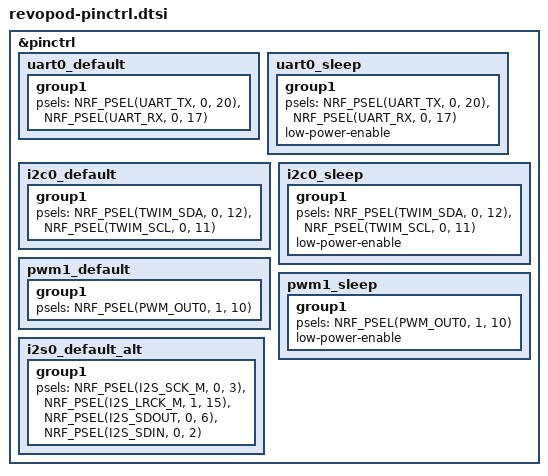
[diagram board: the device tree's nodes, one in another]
/*
 * Copyright (c) 2022 Nordic Semiconductor
 * SPDX-License-Identifier: Apache-2.0
 */

&pinctrl {
	uart0_default: uart0_default {
		group1 {
			psels = <NRF_PSEL(UART_TX, 0, 20)>,
				<NRF_PSEL(UART_RX, 0, 17)>;
		};
	};

	uart0_sleep: uart0_sleep {
		group1 {
			psels = <NRF_PSEL(UART_TX, 0, 20)>,
				<NRF_PSEL(UART_RX, 0, 17)>;
			low-power-enable;
		};
	};

	i2c0_default: i2c0_default {
		group1 {
			psels = <NRF_PSEL(TWIM_SDA, 0, 12)>,
				<NRF_PSEL(TWIM_SCL, 0, 11)>;
		};
	};

	i2c0_sleep: i2c0_sleep {
		group1 {
			psels = <NRF_PSEL(TWIM_SDA, 0, 12)>,
				<NRF_PSEL(TWIM_SCL, 0, 11)>;
			low-power-enable;
		};
	};

	pwm1_default: pwm1_default {
		group1 {
			psels = <NRF_PSEL(PWM_OUT0, 1, 10)>;

		};
	};

	pwm1_sleep: pwm1_sleep {
		group1 {
			psels = <NRF_PSEL(PWM_OUT0, 1, 10)>;
			low-power-enable;
		};
	};
	// spi1_default: spi1_default {
    //     group1 {
    //         psels = <NRF_PSEL(SPIM_SCK, 0, 31)>,
    //             <NRF_PSEL(SPIM_MOSI, 0, 6)>,
    //             <NRF_PSEL(SPIM_MISO, 0, 2)>;
    //     };
    // };
	// spi1_sleep: spi1_sleep {
    //     group1 {
    //         psels = <NRF_PSEL(SPIM_SCK, 0, 31)>,
    //             <NRF_PSEL(SPIM_MOSI, 0, 6)>,
    //             <NRF_PSEL(SPIM_MISO, 0, 2)>;
    //         low-power-enable;
    //     };
	// };
	// spi1_default: spi1_default {
    //     group1 {
    //         psels = <NRF_PSEL(SPIM_MOSI, 0, 6)>;
    //     };
    // };

    // spi1_sleep: spi1_sleep {
    //     group1 {
    //         psels = <NRF_PSEL(SPIM_MOSI, 0, 6)>;
    //         low-power-enable;
    //     };
    // };

	i2s0_default_alt: i2s0_default_alt {
		group1 {
			psels = <NRF_PSEL(I2S_SCK_M, 0, 3)>,
				<NRF_PSEL(I2S_LRCK_M, 1, 15)>,
				<NRF_PSEL(I2S_SDOUT, 0, 6)>, //useful out pin
				<NRF_PSEL(I2S_SDIN, 0, 2)>;
		};
	};
};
